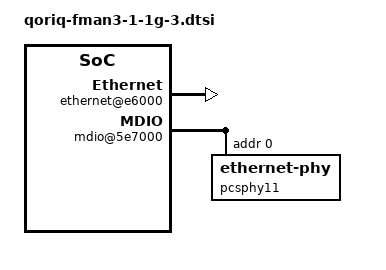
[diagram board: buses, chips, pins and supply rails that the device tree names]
// SPDX-License-Identifier: (GPL-2.0+ OR BSD-3-Clause)
/*
 * QorIQ FMan v3 1g port #3 device tree stub [ controller @ offset 0x500000 ]
 *
 * Copyright 2012 - 2015 Freescale Semiconductor Inc.
 * Copyright 2020 NXP
 *
 */

fman@500000 {
	fman1_rx_0x0b: port@8b000 {
		cell-index = <0xb>;
		compatible = "fsl,fman-v3-port-rx";
		reg = <0x8b000 0x1000>;
	};

	fman1_tx_0x2b: port@ab000 {
		cell-index = <0x2b>;
		compatible = "fsl,fman-v3-port-tx";
		reg = <0xab000 0x1000>;
	};

	ethernet@e6000 {
		cell-index = <3>;
		compatible = "fsl,fman-memac";
		reg = <0xe6000 0x1000>;
		fsl,fman-ports = <&fman1_rx_0x0b &fman1_tx_0x2b>;
		ptp-timer = <&ptp_timer1>;
		pcsphy-handle = <&pcsphy11>;
	};

	mdio@5e7000 {
		#address-cells = <1>;
		#size-cells = <0>;
		compatible = "fsl,fman-memac-mdio", "fsl,fman-xmdio";
		reg = <0xe7000 0x1000>;
		fsl,erratum-a011043; /* must ignore read errors */

		pcsphy11: ethernet-phy@0 {
			reg = <0x0>;
		};
	};
};
